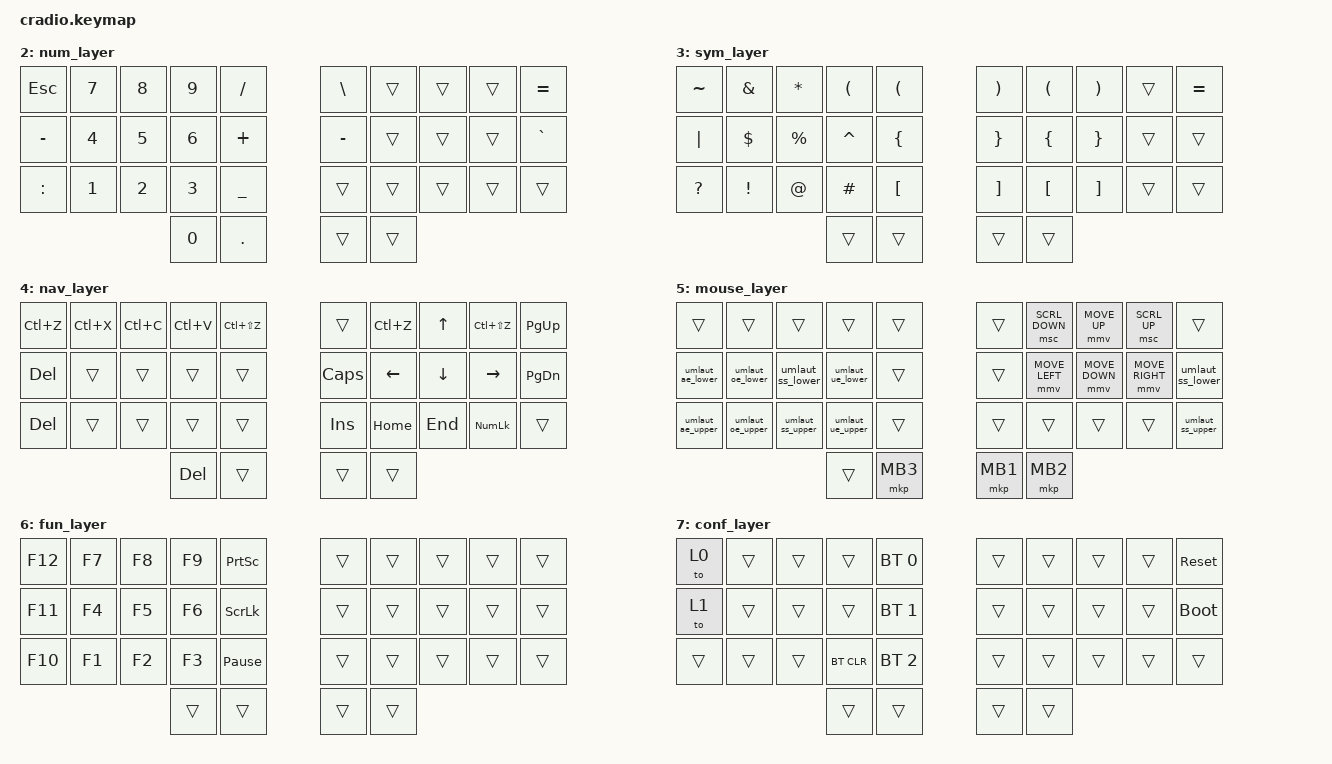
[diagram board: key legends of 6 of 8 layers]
// Copyright (c) 2022 The ZMK Contributors
// SPDX-License-Identifier: MIT

#include <behaviors.dtsi>
#include <dt-bindings/zmk/keys.h>
#include <dt-bindings/zmk/bt.h>
#include <dt-bindings/zmk/pointing.h>

// Home row mods macro
#define HRML(k1,k2,k3,k4) &ht LGUI k1  &ht LALT k2  &ht LCTRL k3  &ht LSHFT k4
#define HRMR(k1,k2,k3,k4) &ht RSHFT k1  &ht RCTRL k2  &ht RALT k3  &ht RGUI k4



/ {
    behaviors {

        // Lowercase umlauts
        umlaut_ae_lower: umlaut_ae_lower {
            compatible = "zmk,behavior-macro";
            #binding-cells = <0>;
            wait-ms = <40>;
            tap-ms = <40>;
            bindings
                = <&macro_press   &kp LALT>
                , <&macro_tap     &kp KP_N0 &kp KP_N2 &kp KP_N2 &kp KP_N8>
                , <&macro_release &kp LALT>
                ;
        };

        umlaut_oe_lower: umlaut_oe_lower {
            compatible = "zmk,behavior-macro";
            #binding-cells = <0>;
            wait-ms = <40>;
            tap-ms = <40>;
            bindings
                = <&macro_press   &kp LALT>
                , <&macro_tap     &kp KP_N0 &kp KP_N2 &kp KP_N4 &kp KP_N6>
                , <&macro_release &kp LALT>
                ;
        };

        umlaut_ue_lower: umlaut_ue_lower {
            compatible = "zmk,behavior-macro";
            #binding-cells = <0>;
            wait-ms = <40>;
            tap-ms = <40>;
            bindings
                = <&macro_press   &kp LALT>
                , <&macro_tap     &kp KP_N0 &kp KP_N2 &kp KP_N5 &kp KP_N2>
                , <&macro_release &kp LALT>
                ;
        };

        umlaut_ss_lower: umlaut_ss_lower {
            compatible = "zmk,behavior-macro";
            #binding-cells = <0>;
            wait-ms = <40>;
            tap-ms = <40>;
            bindings
                = <&macro_press   &kp LALT>
                , <&macro_tap     &kp KP_N0 &kp KP_N2 &kp KP_N2 &kp KP_N3>
                , <&macro_release &kp LALT>
                ;
        };

        // Uppercase umlauts
        umlaut_ae_upper: umlaut_AE_upper {
            compatible = "zmk,behavior-macro";
            #binding-cells = <0>;
            wait-ms = <40>;
            tap-ms = <40>;
            bindings
                = <&macro_press   &kp LALT>
                , <&macro_tap     &kp KP_N0 &kp KP_N1 &kp KP_N9 &kp KP_N6>
                , <&macro_release &kp LALT>
                ;
        };

        umlaut_oe_upper: umlaut_OE_upper {
            compatible = "zmk,behavior-macro";
            #binding-cells = <0>;
            wait-ms = <40>;
            tap-ms = <40>;
            bindings
                = <&macro_press   &kp LALT>
                , <&macro_tap     &kp KP_N0 &kp KP_N2 &kp KP_N1 &kp KP_N4>
                , <&macro_release &kp LALT>
                ;
        };

        umlaut_ue_upper: umlaut_UE_upper {
            compatible = "zmk,behavior-macro";
            #binding-cells = <0>;
            wait-ms = <40>;
            tap-ms = <40>;
            bindings
                = <&macro_press   &kp LALT>
                , <&macro_tap     &kp KP_N0 &kp KP_N2 &kp KP_N2 &kp KP_N0>
                , <&macro_release &kp LALT>
                ;
        };

        umlaut_ss_upper: umlaut_SS_upper {
            compatible = "zmk,behavior-macro";
            #binding-cells = <0>;
            wait-ms = <40>;
            tap-ms = <40>;
            bindings
                = <&macro_press   &kp LALT>
                , <&macro_tap     &kp KP_N7 &kp KP_N8 &kp KP_N3 &kp KP_N8>
                , <&macro_release &kp LALT>
                ;
        };
    };
};


// Mods for writing umlauts using alt codes (only on windows). 
/ {

    behaviors {
        ht: hold_tap {
            compatible = "zmk,behavior-hold-tap";
            #binding-cells = <2>;
            flavor = "tap-preferred";
            tapping-term-ms = <200>;
            quick-tap-ms = <150>;
            require-prior-idle-ms = <100>;
            bindings = <&kp>, <&kp>;
        };
    };

    conditional_layers {
        compatible = "zmk,conditional-layers";
        fun_layer {
            if-layers = <2 3>;
            then-layer = <6>;
        };
        conf_layer {
            if-layers = <3 5>;
            then-layer = <7>;
        };
    };

    keymap {
        compatible = "zmk,keymap";
        default_layer {
            bindings = <
        //╭──────────┬──────────┬──────────┬──────────┬──────────╮   ╭──────────┬──────────┬──────────┬──────────┬──────────╮
        //│  ' "     │  , <     │  . >     │  P       │  Y       │   │  F       │  G       │  C       │  R       │  L       │
            &kp SQT   &kp COMMA  &kp DOT     &kp P      &kp Y          &kp F      &kp G      &kp C      &kp R      &kp L
        //├──────────┼──────────┼──────────┼──────────┼──────────┤   ├──────────┼──────────┼──────────┼──────────┼──────────┤
        //│  A       │  O       │  E       │  U       │  I       │   │  D       │  H       │  T       │  N       │  S       │
            HRML(A,        O,         E,         U)     &kp I          &kp D      HRMR(H,        T,         N,           S)
        //├──────────┼──────────┼──────────┼──────────┼──────────┤   ├──────────┼──────────┼──────────┼──────────┼──────────┤
        //│  ; :     │  Q       │  J       │  K       │  X       │   │  B       │  M       │ W        │ V        │  Z       │
            &kp SEMI      &kp Q      &kp J      &kp K      &kp X          &kp B      &kp M    &kp W       &kp V    &kp Z
        //╰──────────┴──────────┴──────────┼──────────┼──────────┤   ├──────────┼──────────┼──────────┴──────────┴──────────╯
                                            &lt 5 TAB  &lt 4 BSPC     &lt 2 SPACE &lt 3 ENTER
        //                                 ╰──────────┴──────────╯   ╰──────────┴──────────╯
            >;
        };

// LAYER 1

        qwerty_layer {
            bindings = <
        //╭──────────┬──────────┬──────────┬──────────┬──────────╮   ╭──────────┬──────────┬──────────┬──────────┬──────────╮
        //│  Q       │  W       │  E       │  R       │  T       │   │  Y       │  U       │  I       │  O       │  P       │
            &kp Q      &kp W      &kp E      &kp R      &kp T          &kp Y      &kp U      &kp I      &kp O      &kp P
        //├──────────┼──────────┼──────────┼──────────┼──────────┤   ├──────────┼──────────┼──────────┼──────────┼──────────┤
        //│  A       │  S       │  D       │  F       │  G       │   │  H       │  J       │  K       │  L       │ ' "      │
            HRML(A,        S,         D,         F)     &kp G          &kp H      HRMR(J,        K,         L,        SQT)
        //├──────────┼──────────┼──────────┼──────────┼──────────┤   ├──────────┼──────────┼──────────┼──────────┼──────────┤
        //│  Z       │  X       │  C       │  V       │  B       │   │  N       │  M       │ , <      │ . >      │ / ?      │
            &kp Z      &kp X      &kp C      &kp V      &kp B          &kp N      &kp M      &kp COMMA  &kp DOT    &kp FSLH
        //╰──────────┴──────────┴──────────┼──────────┼──────────┤   ├──────────┼──────────┼──────────┴──────────┴──────────╯
                                            &lt 5 TAB  &lt 4 BSPC     &lt 2 SPACE &lt 3 ENTER
        //                                 ╰──────────┴──────────╯   ╰──────────┴──────────╯
            >;
        };


// LAYER 2 - Numbers on the left side

        num_layer {
            bindings = <
        //╭──────────┬──────────┬──────────┬──────────┬──────────╮   ╭──────────┬──────────┬──────────┬──────────┬──────────╮
        //│  ESC     │  7       │  8       │  9       │  /       │   │  \       │          │          │          │  =       │
            &kp ESC    &kp N7     &kp N8     &kp N9    &kp FSLH      &kp BSLH     &trans      &trans   &trans    &kp EQUAL
        //├──────────┼──────────┼──────────┼──────────┼──────────┤   ├──────────┼──────────┼──────────┼──────────┼──────────┤
        //│  -       │  4       │  5       │  6       │  +       │   │  -       │          │          │          │  `       │
            &kp MINUS    &kp N4     &kp N5     &kp N6    &kp PLUS      &kp MINUS    &trans   &trans      &trans     &kp GRAVE
        //├──────────┼──────────┼──────────┼──────────┼──────────┤   ├──────────┼──────────┼──────────┼──────────┼──────────┤
        //│  :       │  1       │  2       │  3       │  _       │   │          │          │          │          │          │
           &kp COLON  &kp N1     &kp N2     &kp N3     &kp UNDER      &trans     &trans     &trans     &trans     &trans
        //╰──────────┴──────────┴──────────┼──────────┼──────────┤   ├──────────┼──────────┼──────────┴──────────┴──────────╯
                                             &kp N0    &kp DOT        &trans     &trans
        //                                 ╰──────────┴──────────╯   ╰──────────┴──────────╯
            >;
        };

// LAYER 3 - Symbols on the left side

        sym_layer {
            bindings = <
        //╭──────────┬──────────┬──────────┬──────────┬──────────╮   ╭──────────┬──────────┬──────────┬──────────┬──────────╮
        //│  ~       │  &       │  *       │  ()      │  (       │   │  )       │  (       │  )       │          │  =       │
           &kp TILDE    &kp AMPS   &kp ASTRK   &kp LPAR   &kp LPAR     &kp RPAR   &kp LPAR   &kp RPAR   &trans   &kp EQUAL
        //├──────────┼──────────┼──────────┼──────────┼──────────┤   ├──────────┼──────────┼──────────┼──────────┼──────────┤
        //│  |       │  $       │  %       │  ^       │  {       │   │  }       │  {       │  }       │          │          │
            &kp PIPE   &kp DLLR  &kp PRCNT   &kp CARET   &kp LBRC      &kp RBRC    &kp LBRC  &kp RBRC   &trans      &trans
        //├──────────┼──────────┼──────────┼──────────┼──────────┤   ├──────────┼──────────┼──────────┼──────────┼──────────┤
        //│  ?       │  !       │  @       │   #      │    [     │   │  ]       │  [       │  ]       │          │          │
            &kp QMARK  &kp EXCL    &kp AT    &kp HASH    &kp LBKT       &kp RBKT   &kp LBKT   &kp RBKT   &trans     &trans
        //╰──────────┴──────────┴──────────┼──────────┼──────────┤   ├──────────┼──────────┼──────────┴──────────┴──────────╯
                                             &trans     &trans         &trans     &trans
        //                                 ╰──────────┴──────────╯   ╰──────────┴──────────╯
            >;
        };

// LAYER 4 - NAV navigation on the right


        nav_layer {
            bindings = <
        //╭──────────┬──────────┬──────────┬──────────┬──────────╮   ╭──────────┬──────────┬──────────┬──────────┬──────────╮
        //│  Undo    │    Cut   │    Copy  │   Paste  │  Redo    │   │          │  Undo    │    UP    │   Redo   │ Page Up  │
            &kp LC(Z)    &kp LC(X)  &kp LC(C)  &kp LC(V) &kp LC(LS(Z))  &trans   &kp LC(Z)   &kp UP  &kp LC(LS(Z))  &kp PG_UP
        //├──────────┼──────────┼──────────┼──────────┼──────────┤   ├──────────┼──────────┼──────────┼──────────┼──────────┤
        //│          │          │          │          │          │   │          │  LEFT    │   DOWN   │  RIGHT   │ Page Down│
             &kp DEL    &trans     &trans     &trans    &trans        &kp CAPS    &kp LEFT  &kp DOWN   &kp RIGHT   &kp PG_DN
        //├──────────┼──────────┼──────────┼──────────┼──────────┤   ├──────────┼──────────┼──────────┼──────────┼──────────┤
        //│          │          │          │          │          │   │  Insert  │   Home   │  End     │          │          │
            &kp DEL    &trans     &trans    &trans       &trans         &kp INS   &kp HOME    &kp END     &kp KP_NUM     &trans
        //╰──────────┴──────────┴──────────┼──────────┼──────────┤   ├──────────┼──────────┼──────────┴──────────┴──────────╯
                                             &kp DEL     &trans          &trans     &trans
        //                                 ╰──────────┴──────────╯   ╰──────────┴──────────╯
            >;
        };


// LAYER 5 - mouse


        mouse_layer {
            bindings = <
        //╭──────────┬──────────┬──────────┬──────────┬──────────╮   ╭──────────┬──────────┬──────────┬──────────┬──────────╮
        //│          │          │          │          │          │   │          │ Scrl Down│    UP    │ Scrl Up  │          │
            &trans       &trans     &trans     &trans    &trans    &trans  &msc SCRL_DOWN   &mmv MOVE_UP     &msc SCRL_UP      &trans
        //├──────────┼──────────┼──────────┼──────────┼──────────┤   ├──────────┼──────────┼──────────┼──────────┼──────────┤
        //│          │          │          │          │          │   │          │   LEFT   │  DOWN    │  RIGHT   │          │
             &umlaut_ae_lower      &umlaut_oe_lower     &umlaut_ss_lower     &umlaut_ue_lower    &trans      &trans &mmv MOVE_LEFT &mmv MOVE_DOWN &mmv MOVE_RIGHT  &umlaut_ss_lower
        //├──────────┼──────────┼──────────┼──────────┼──────────┤   ├──────────┼──────────┼──────────┼──────────┼──────────┤
        //│          │          │          │          │          │   │          │          │          │          │          │
            &umlaut_ae_upper     &umlaut_oe_upper     &umlaut_ss_upper    &umlaut_ue_upper       &trans         &trans     &trans     &trans     &trans     &umlaut_ss_upper
        //╰──────────┴──────────┴──────────┼──────────┼──────────┤   ├──────────┼──────────┼──────────┴──────────┴──────────╯
                                             &trans     &mkp MB3      &mkp MB1   &mkp MB2
        //                                 ╰──────────┴──────────╯   ╰──────────┴──────────╯
            >;
        };

// LAYER 6 - function layer

        fun_layer {
            bindings = <
        //╭──────────┬──────────┬──────────┬──────────┬──────────╮   ╭──────────┬──────────┬──────────┬──────────┬──────────╮
        //│          │          │          │          │          │   │          │          │          │          │          │
            &kp F12    &kp F7     &kp F8     &kp F9    &kp PSCRN       &trans     &trans     &trans     &trans      &trans
        //├──────────┼──────────┼──────────┼──────────┼──────────┤   ├──────────┼──────────┼──────────┼──────────┼──────────┤
        //│          │          │          │          │          │   │          │          │          │          │          │
             &kp F11   &kp F4     &kp F5     &kp F6      &kp SLCK       &trans     &trans     &trans     &trans    &trans
        //├──────────┼──────────┼──────────┼──────────┼──────────┤   ├──────────┼──────────┼──────────┼──────────┼──────────┤
        //│          │          │          │          │          │   │          │          │          │          │          │
            &kp F10     &kp F1     &kp F2    &kp F3      &kp PAUSE_BREAK         &trans     &trans     &trans     &trans     &trans
        //╰──────────┴──────────┴──────────┼──────────┼──────────┤   ├──────────┼──────────┼──────────┴──────────┴──────────╯
                                             &trans     &trans         &trans     &trans
        //                                 ╰──────────┴──────────╯   ╰──────────┴──────────╯
            >;
        };

// LAYER 7 - config layer

        conf_layer {
            bindings = <
        //╭──────────┬──────────┬──────────┬──────────┬──────────╮   ╭──────────┬──────────┬──────────┬──────────┬──────────╮
        //│ DVORAK   │          │          │          │PROFILE 0 │   │          │          │          │          │  RESET   │
           &to 0        &trans     &trans     &trans    &bt BT_SEL 0    &trans     &trans     &trans     &trans    &sys_reset
        //├──────────┼──────────┼──────────┼──────────┼──────────┤   ├──────────┼──────────┼──────────┼──────────┼──────────┤
        //QUERTY     |          │          │          │PROFILE 1 │   │          │          │          │          │BOOTLOADER│
            &to 1      &trans     &trans     &trans    &bt BT_SEL 1    &trans     &trans     &trans     &trans    &bootloader
        //├──────────┼──────────┼──────────┼──────────┼──────────┤   ├──────────┼──────────┼──────────┼──────────┼──────────┤
        //│          │          │          │ CLEAR BT │PROFILE 2 │   │          │          │          │          │          │
            &trans     &trans     &trans    &bt BT_CLR &bt BT_SEL 2    &trans     &trans     &trans     &trans     &trans
        //╰──────────┴──────────┴──────────┼──────────┼──────────┤   ├──────────┼──────────┼──────────┴──────────┴──────────╯
                                             &trans     &trans         &trans     &trans
        //                                 ╰──────────┴──────────╯   ╰──────────┴──────────╯
            >;
        };





//        nav_layer {
//            bindings = <
        //╭──────────┬──────────┬──────────┬──────────┬──────────╮   ╭──────────┬──────────┬──────────┬──────────┬──────────╮
        //│          │          │          │          │          │   │          │          │          │          │          │
//            &trans       &trans     &trans     &trans    &trans         &trans     &trans     &trans     &trans      &trans
        //├──────────┼──────────┼──────────┼──────────┼──────────┤   ├──────────┼──────────┼──────────┼──────────┼──────────┤
        //│          │          │          │          │          │   │          │          │          │          │          │
//             &trans      &trans     &trans     &trans    &trans          &trans     &trans     &trans     &trans    &trans
        //├──────────┼──────────┼──────────┼──────────┼──────────┤   ├──────────┼──────────┼──────────┼──────────┼──────────┤
        //│          │          │          │          │          │   │          │          │          │          │          │
//            &trans     &trans     &trans    &trans       &trans         &trans     &trans     &trans     &trans     &trans
        //╰──────────┴──────────┴──────────┼──────────┼──────────┤   ├──────────┼──────────┼──────────┴──────────┴──────────╯
//                                             &trans     &trans         &trans     &trans
        //                                 ╰──────────┴──────────╯   ╰──────────┴──────────╯
//            >;
//        };
    };
};
